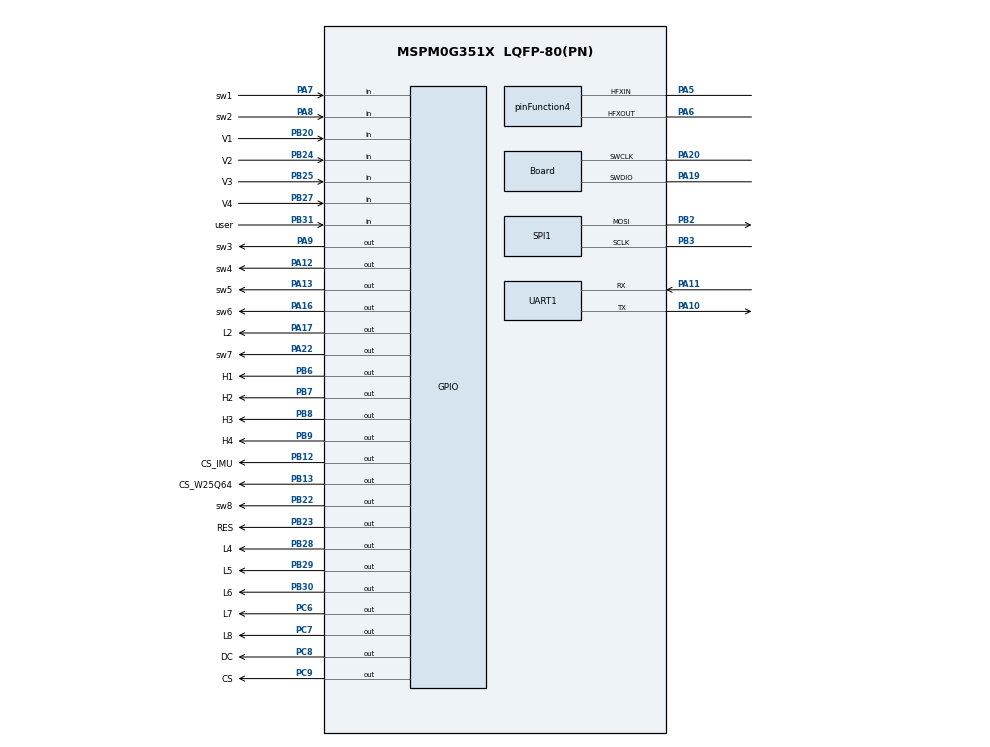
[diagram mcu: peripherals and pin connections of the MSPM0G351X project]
/**
 * @cliArgs --device "MSPM0G351X" --part "Default" --package "LQFP-80(PN)" --product "mspm0_sdk@2.08.00.03"
 * @versions {"tool":"1.25.0+4268"}
 */

/**
 * Import the modules used in this configuration.
 */
const ADC12         = scripting.addModule("/ti/driverlib/ADC12", {}, false);
const ADC121        = ADC12.addInstance();
const DAC12         = scripting.addModule("/ti/driverlib/DAC12");
const GPIO          = scripting.addModule("/ti/driverlib/GPIO", {}, false);
const GPIO1         = GPIO.addInstance();
const GPIO2         = GPIO.addInstance();
const GPIO3         = GPIO.addInstance();
const GPIO4         = GPIO.addInstance();
const GPIO5         = GPIO.addInstance();
const GPIO6         = GPIO.addInstance();
const GPIO7         = GPIO.addInstance();
const GPIO8         = GPIO.addInstance();
const SPI           = scripting.addModule("/ti/driverlib/SPI", {}, false);
const SPI1          = SPI.addInstance();
const SYSCTL        = scripting.addModule("/ti/driverlib/SYSCTL");
const TIMER         = scripting.addModule("/ti/driverlib/TIMER", {}, false);
const TIMER1        = TIMER.addInstance();
const TRNG          = scripting.addModule("/ti/driverlib/TRNG");
const UART          = scripting.addModule("/ti/driverlib/UART", {}, false);
const UART1         = UART.addInstance();
const ProjectConfig = scripting.addModule("/ti/project_config/ProjectConfig");

/**
 * Write custom configuration values to the imported modules.
 */
const divider2       = system.clockTree["HFCLK4MFPCLKDIV"];
divider2.divideValue = 10;

const divider9       = system.clockTree["UDIV"];
divider9.divideValue = 2;

const gate7  = system.clockTree["MFCLKGATE"];
gate7.enable = true;

const gate8  = system.clockTree["MFPCLKGATE"];
gate8.enable = true;

const multiplier2         = system.clockTree["PLL_QDIV"];
multiplier2.multiplyValue = 4;

const mux4       = system.clockTree["EXHFMUX"];
mux4.inputSelect = "EXHFMUX_XTAL";

const mux8       = system.clockTree["HSCLKMUX"];
mux8.inputSelect = "HSCLKMUX_SYSPLL0";

const mux10       = system.clockTree["MFPCLKMUX"];
mux10.inputSelect = "MFPCLKMUX_HFCLK";

const mux12       = system.clockTree["SYSPLLMUX"];
mux12.inputSelect = "zSYSPLLMUX_HFCLK";

const pinFunction4                        = system.clockTree["HFXT"];
pinFunction4.inputFreq                    = 40;
pinFunction4.enable                       = true;
pinFunction4.HFXTStartup                  = 10;
pinFunction4.peripheral.$assign           = "SYSCTL";
pinFunction4.peripheral.hfxInPin.$assign  = "PA5";
pinFunction4.peripheral.hfxOutPin.$assign = "PA6";

const pinFunction6     = system.clockTree["LFXT"];
pinFunction6.inputFreq = 32.768;

ADC121.$name                      = "ADC12_0";
ADC121.sampClkDiv                 = "DL_ADC12_CLOCK_DIVIDE_8";
ADC121.adcMem0avgen               = true;
ADC121.sampleTime0                = "0.1 ms";
ADC121.sampleTime1                = "0.1ms";
ADC121.enabledInterrupts          = ["DL_ADC12_INTERRUPT_MEM0_RESULT_LOADED"];
ADC121.enableDMA                  = false;
ADC121.peripheral.$assign         = "ADC0";
ADC121.peripheral.adcPin0.$assign = "PA27";
ADC121.adcPin0Config.$name        = "ti_driverlib_gpio_GPIOPinGeneric5";
ADC121.adcPin0Config.enableConfig = true;

const Board                       = scripting.addModule("/ti/driverlib/Board", {}, false);
Board.peripheral.$assign          = "DEBUGSS";
Board.peripheral.swclkPin.$assign = "PA20";
Board.peripheral.swdioPin.$assign = "PA19";

DAC12.dacOutputPinEn           = true;
DAC12.dacSampleTimerEn         = true;
DAC12.dacFIFOEn                = true;
DAC12.dacConfigureDMA          = true;
DAC12.dacFIFOThresh            = "TWO_QTRS_EMPTY";
DAC12.dacSampleTimerRate       = "200K";
DAC12.dacAmplifier             = "ON";
DAC12.OutPinConfig.$name       = "ti_driverlib_gpio_GPIOPinGeneric6";
DAC12.DMA_CHANNEL.$name        = "DMA_CH0";
DAC12.DMA_CHANNEL.addressMode  = "b2f";
DAC12.DMA_CHANNEL.srcLength    = "HALF_WORD";
DAC12.DMA_CHANNEL.dstLength    = "HALF_WORD";
DAC12.DMA_CHANNEL.transferMode = "FULL_CH_REPEAT_SINGLE";

GPIO1.$name                                       = "LED";
GPIO1.associatedPins.create(8);
GPIO1.associatedPins[0].$name                     = "L1";
GPIO1.associatedPins[0].internalResistor          = "PULL_UP";
GPIO1.associatedPins[0].initialValue              = "SET";
GPIO1.associatedPins[0].pin.$assignAllowConflicts = "PA14";
GPIO1.associatedPins[1].$name                     = "L2";
GPIO1.associatedPins[1].internalResistor          = "PULL_UP";
GPIO1.associatedPins[1].pin.$assign               = "PA17";
GPIO1.associatedPins[2].$name                     = "L3";
GPIO1.associatedPins[2].internalResistor          = "PULL_UP";
GPIO1.associatedPins[2].pin.$assignAllowConflicts = "PB26";
GPIO1.associatedPins[3].$name                     = "L4";
GPIO1.associatedPins[3].internalResistor          = "PULL_UP";
GPIO1.associatedPins[3].pin.$assign               = "PB28";
GPIO1.associatedPins[4].$name                     = "L5";
GPIO1.associatedPins[4].internalResistor          = "PULL_UP";
GPIO1.associatedPins[4].pin.$assign               = "PB29";
GPIO1.associatedPins[5].$name                     = "L6";
GPIO1.associatedPins[5].internalResistor          = "PULL_UP";
GPIO1.associatedPins[5].pin.$assign               = "PB30";
GPIO1.associatedPins[6].$name                     = "L7";
GPIO1.associatedPins[6].internalResistor          = "PULL_UP";
GPIO1.associatedPins[6].pin.$assign               = "PC6";
GPIO1.associatedPins[7].$name                     = "L8";
GPIO1.associatedPins[7].pin.$assign               = "PC7";

GPIO2.$name                               = "key";
GPIO2.associatedPins[0].$name             = "user";
GPIO2.associatedPins[0].direction         = "INPUT";
GPIO2.associatedPins[0].polarity          = "FALL";
GPIO2.associatedPins[0].internalResistor  = "PULL_UP";
GPIO2.associatedPins[0].assignedPin       = "31";
GPIO2.associatedPins[0].assignedPort      = "PORTB";
GPIO2.associatedPins[0].interruptPriority = "0";
GPIO2.associatedPins[0].pin.$assign       = "PB31";

GPIO3.$name                               = "keyboard";
GPIO3.associatedPins.create(8);
GPIO3.associatedPins[0].$name             = "H1";
GPIO3.associatedPins[0].internalResistor  = "PULL_UP";
GPIO3.associatedPins[0].interruptEn       = true;
GPIO3.associatedPins[0].interruptPriority = "0";
GPIO3.associatedPins[0].polarity          = "FALL";
GPIO3.associatedPins[0].pin.$assign       = "PB6";
GPIO3.associatedPins[1].$name             = "H2";
GPIO3.associatedPins[1].internalResistor  = "PULL_UP";
GPIO3.associatedPins[1].interruptEn       = true;
GPIO3.associatedPins[1].interruptPriority = "0";
GPIO3.associatedPins[1].polarity          = "FALL";
GPIO3.associatedPins[1].pin.$assign       = "PB7";
GPIO3.associatedPins[2].$name             = "H3";
GPIO3.associatedPins[2].internalResistor  = "PULL_UP";
GPIO3.associatedPins[2].pin.$assign       = "PB8";
GPIO3.associatedPins[3].$name             = "H4";
GPIO3.associatedPins[3].internalResistor  = "PULL_UP";
GPIO3.associatedPins[3].pin.$assign       = "PB9";
GPIO3.associatedPins[4].$name             = "V1";
GPIO3.associatedPins[4].direction         = "INPUT";
GPIO3.associatedPins[4].internalResistor  = "PULL_UP";
GPIO3.associatedPins[4].polarity          = "FALL";
GPIO3.associatedPins[4].interruptEn       = true;
GPIO3.associatedPins[4].pin.$assign       = "PB20";
GPIO3.associatedPins[5].$name             = "V2";
GPIO3.associatedPins[5].direction         = "INPUT";
GPIO3.associatedPins[5].internalResistor  = "PULL_UP";
GPIO3.associatedPins[5].interruptEn       = true;
GPIO3.associatedPins[5].interruptPriority = "0";
GPIO3.associatedPins[5].polarity          = "FALL";
GPIO3.associatedPins[5].pin.$assign       = "PB24";
GPIO3.associatedPins[6].$name             = "V3";
GPIO3.associatedPins[6].direction         = "INPUT";
GPIO3.associatedPins[6].internalResistor  = "PULL_UP";
GPIO3.associatedPins[6].polarity          = "FALL";
GPIO3.associatedPins[6].interruptEn       = true;
GPIO3.associatedPins[6].pin.$assign       = "PB25";
GPIO3.associatedPins[7].$name             = "V4";
GPIO3.associatedPins[7].direction         = "INPUT";
GPIO3.associatedPins[7].internalResistor  = "PULL_UP";
GPIO3.associatedPins[7].polarity          = "FALL";
GPIO3.associatedPins[7].interruptEn       = true;
GPIO3.associatedPins[7].pin.$assign       = "PB27";

GPIO4.$name                              = "OLED";
GPIO4.associatedPins.create(3);
GPIO4.associatedPins[0].$name            = "RES";
GPIO4.associatedPins[0].pin.$assign      = "PB23";
GPIO4.associatedPins[1].$name            = "DC";
GPIO4.associatedPins[1].pin.$assign      = "PC8";
GPIO4.associatedPins[2].$name            = "CS";
GPIO4.associatedPins[2].internalResistor = "PULL_UP";
GPIO4.associatedPins[2].pin.$assign      = "PC9";

GPIO5.$name                              = "IMU";
GPIO5.associatedPins[0].$name            = "CS_IMU";
GPIO5.associatedPins[0].internalResistor = "PULL_UP";
GPIO5.associatedPins[0].pin.$assign      = "PB12";

GPIO6.$name                              = "W25Q64";
GPIO6.associatedPins[0].$name            = "CS_W25Q64";
GPIO6.associatedPins[0].internalResistor = "PULL_UP";
GPIO6.associatedPins[0].pin.$assign      = "PB13";

GPIO7.$name                         = "switch";
GPIO7.associatedPins.create(8);
GPIO7.associatedPins[0].$name       = "sw1";
GPIO7.associatedPins[0].direction   = "INPUT";
GPIO7.associatedPins[0].pin.$assign = "PA7";
GPIO7.associatedPins[1].$name       = "sw2";
GPIO7.associatedPins[1].direction   = "INPUT";
GPIO7.associatedPins[1].pin.$assign = "PA8";
GPIO7.associatedPins[2].$name       = "sw3";
GPIO7.associatedPins[2].pin.$assign = "PA9";
GPIO7.associatedPins[3].$name       = "sw4";
GPIO7.associatedPins[3].pin.$assign = "PA12";
GPIO7.associatedPins[4].$name       = "sw5";
GPIO7.associatedPins[4].pin.$assign = "PA13";
GPIO7.associatedPins[5].$name       = "sw6";
GPIO7.associatedPins[5].pin.$assign = "PA16";
GPIO7.associatedPins[6].$name       = "sw7";
GPIO7.associatedPins[6].pin.$assign = "PA22";
GPIO7.associatedPins[7].$name       = "sw8";
GPIO7.associatedPins[7].pin.$assign = "PB22";

GPIO8.$name                                       = "LedBoard";
GPIO8.associatedPins[0].$name                     = "LB1";
GPIO8.associatedPins[0].assignedPort              = "PORTA";
GPIO8.associatedPins[0].assignedPin               = "14";
GPIO8.associatedPins[0].internalResistor          = "PULL_UP";
GPIO8.associatedPins[0].pin.$assignAllowConflicts = "PA14";

SPI1.$name                      = "SPI_0";
SPI1.direction                  = "PICO";
SPI1.chipSelect                 = [];
SPI1.frameFormat                = "MOTO3";
SPI1.targetBitRate              = 10000000;
SPI1.sclkPinConfig.$name        = "ti_driverlib_gpio_GPIOPinGeneric0";
SPI1.mosiPinConfig.$name        = "ti_driverlib_gpio_GPIOPinGeneric1";
SPI1.peripheral.sclkPin.$assign = "PB3";
SPI1.peripheral.mosiPin.$assign = "PB2";

SYSCTL.forceDefaultClkConfig = true;
SYSCTL.clockTreeEn           = true;

TIMER1.$name              = "TIMER_0";
TIMER1.timerClkSrc        = "MFCLK";
TIMER1.timerClkPrescale   = 100;
TIMER1.timerMode          = "PERIODIC";
TIMER1.interrupts         = ["ZERO"];
TIMER1.timerPeriod        = "100ms";
TIMER1.peripheral.$assign = "TIMG8";

TRNG.clockDivider = "DL_TRNG_CLOCK_DIVIDE_8";

UART1.$name                    = "UART_0";
UART1.enabledInterrupts        = ["RX"];
UART1.targetBaudRate           = 115200;
UART1.peripheral.$assign       = "UART0";
UART1.peripheral.rxPin.$assign = "PA11";
UART1.peripheral.txPin.$assign = "PA10";
UART1.txPinConfig.$name        = "ti_driverlib_gpio_GPIOPinGeneric3";
UART1.rxPinConfig.$name        = "ti_driverlib_gpio_GPIOPinGeneric4";

ProjectConfig.migrationCondition = true;
ProjectConfig.genLibCMSIS        = true;
ProjectConfig.compiler           = "ticlang";

/**
 * Pinmux solution for unlocked pins/peripherals. This ensures that minor changes to the automatic solver in a future
 * version of the tool will not impact the pinmux you originally saw.  These lines can be completely deleted in order to
 * re-solve from scratch.
 */
DAC12.peripheral.$suggestSolution             = "DAC0";
DAC12.peripheral.OutPin.$suggestSolution      = "PA15";
DAC12.DMA_CHANNEL.peripheral.$suggestSolution = "DMA_CH0";
SPI1.peripheral.$suggestSolution              = "SPI0";
